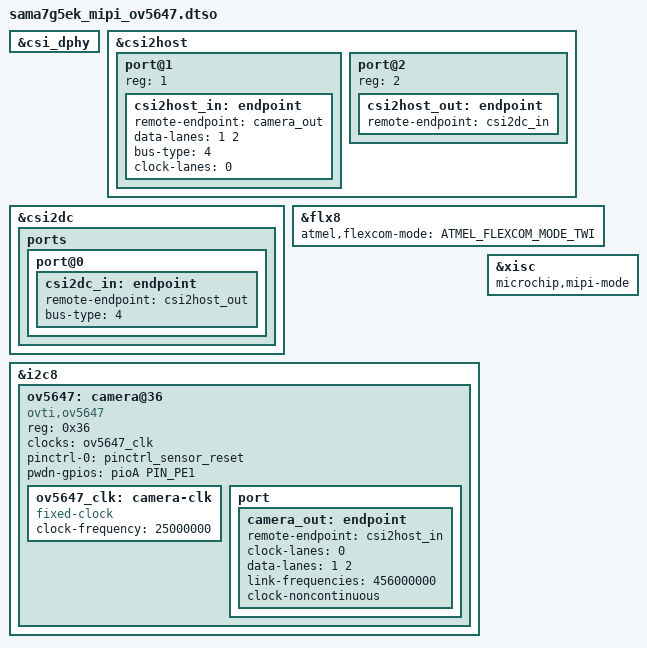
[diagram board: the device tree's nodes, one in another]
// SPDX-License-Identifier: (GPL-2.0+ OR MIT)
/*
 * Device Tree file for SAMA7G5-EK board
 * overlay blob for MIPI with ov5647 sensor. The blob uses MIPI and i2c8
 *
 * Copyright (C) 2024 Microchip Technology Inc. and its subsidiaries
 * Author: Vasanthaselvam R
 *
 */
/dts-v1/;
/plugin/;

#include "sama7g5-pinfunc.h"
#include <dt-bindings/gpio/gpio.h>
#include <dt-bindings/mfd/atmel-flexcom.h>

&csi_dphy {
	status = "okay";
};


&csi2host {
	#address-cells = <1>;
	#size-cells = <0>;

	status = "okay";

	port@1 {
		reg = <1>;
		csi2host_in: endpoint {
			remote-endpoint = <&camera_out>;
			data-lanes = <1 2>;
			bus-type = <4>;
			clock-lanes = <0>;
		};
	};

	port@2 {
		reg = <2>;
		csi2host_out: endpoint {
			remote-endpoint = <&csi2dc_in>;
		};
	};
};

&csi2dc {
	status = "okay";

	ports {
		port@0 {
			csi2dc_in: endpoint {
				remote-endpoint = <&csi2host_out>;
				bus-type = <4>; /* MIPI CSI2 D-PHY */
			};
		};
	};
};

&flx8 {
	atmel,flexcom-mode = <ATMEL_FLEXCOM_MODE_TWI>;
	status = "okay";
};

&i2c8 {
	/*
	 * Camera sensor add-on for OV5647-MIPI-CS
	 *
	 *
	 * Sensor i2c address is fixed at 0x36
	 *
	 */

		#address-cells= <1>;
		#size-cells= <0>;
		ov5647: camera@36 {
            		compatible = "ovti,ov5647";
			reg = <0x36>;
            		clocks = <&ov5647_clk>;
			pinctrl-names = "default";
			pinctrl-0 = <&pinctrl_sensor_reset>;
            		pwdn-gpios = <&pioA PIN_PE1 GPIO_ACTIVE_HIGH>;

			ov5647_clk: camera-clk {
				compatible = "fixed-clock";
				#clock-cells = <0>;
				clock-frequency = <25000000>;     //The clock frequency is fixed at 25MHz
				};


            		port {
                		camera_out: endpoint {
                   	 		remote-endpoint = <&csi2host_in>;
					clock-lanes = <0>;
					data-lanes = <1 2>;
					link-frequencies = /bits/ 64 <456000000>;
					clock-noncontinuous;
               				};
            		};
        	};
    	

 };

&xisc {
	microchip,mipi-mode;
	status = "okay";
};


